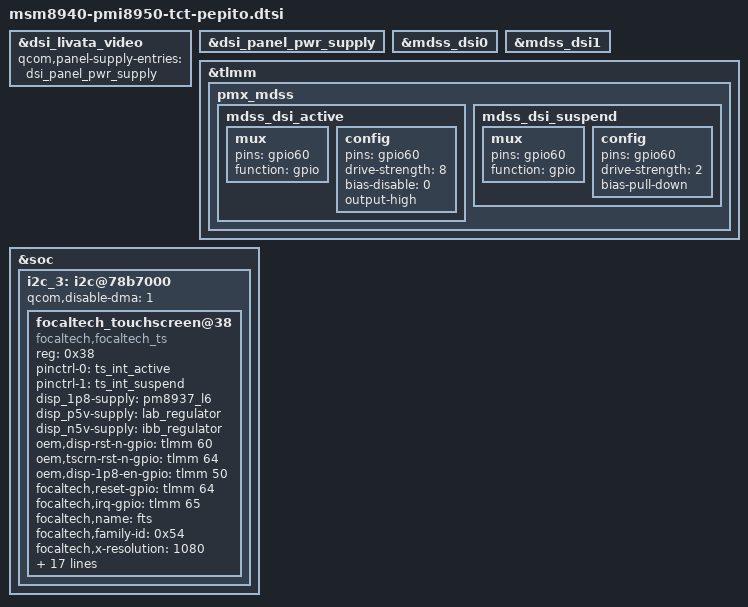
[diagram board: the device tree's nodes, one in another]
#include "dsi-panel-livata-juno-video.dtsi"
&dsi_livata_video {
	qcom,panel-supply-entries = <&dsi_panel_pwr_supply>;
};

&dsi_panel_pwr_supply {
	/* On Mercury, The touch driver controls vregs and gpios */
	/delete-node/ qcom,panel-supply-entry@1;
	/delete-node/ qcom,panel-supply-entry@2;
	/delete-node/ qcom,panel-supply-entry@3;
};

&mdss_dsi0 {
	/* On Mercury, The touch driver controls vregs and gpios */
	/delete-property/ vddio-supply;
	/delete-property/ lab-supply;
	/delete-property/ ibb-supply;

	/delete-property/ qcom,platform-enable-gpio;
	/delete-property/ qcom,5v-boost-gpio;
	/delete-property/ qcom,platform-bklight-en-gpio;
	/delete-property/ qcom,platform-reset-gpio;
};

&mdss_dsi1 {
	/* On Mercury, The touch driver controls vregs and gpios */
	/delete-property/ vddio-supply;
	/delete-property/ lab-supply;
	/delete-property/ ibb-supply;

	/delete-property/ qcom,platform-enable-gpio;
	/delete-property/ qcom,5v-boost-gpio;
	/delete-property/ qcom,platform-bklight-en-gpio;
	/delete-property/ qcom,platform-reset-gpio;
};

&tlmm {
	/delete-node/pmx_mdss;
	pmx_mdss: pmx_mdss {
		mdss_dsi_active: mdss_dsi_active {
			mux {
				pins = "gpio60";
				function = "gpio";
			};

			config {
				pins = "gpio60";
				drive-strength = <8>; /* 8 mA */
				bias-disable = <0>; /* no pull */
				output-high;
			};
		};

		mdss_dsi_suspend: mdss_dsi_suspend {
			mux {
				pins = "gpio60";
				function = "gpio";
			};

			config {
				pins = "gpio60";
				drive-strength = <2>; /* 2 mA */
				bias-pull-down; /* pull down */
			};
		};
	};
};
&soc {
	i2c_3: i2c@78b7000 { /* BLSP1 QUP3 */
		qcom,disable-dma = <1>;
		status = "okay";

		focaltech_touchscreen@38 {
			compatible = "focaltech,focaltech_ts";
			reg = <0x38>;
			/*interrupt-parent = <&msm_gpio>;*/
			/*interrupts = <13 0x8>;*/
			pinctrl-names = "on_state", "off_state";
			pinctrl-0 = <&ts_int_active>;
			pinctrl-1 = <&ts_int_suspend>;

			disp_1p8-supply     	= <&pm8937_l6>;
			disp_p5v-supply 	= <&lab_regulator>;
			disp_n5v-supply 	= <&ibb_regulator>;
			oem,disp-rst-n-gpio = <&tlmm 60 0x00>;
			oem,tscrn-rst-n-gpio = <&tlmm 64 0x00>;
			oem,disp-1p8-en-gpio = <&tlmm 50 0x00>;
			focaltech,reset-gpio = <&tlmm 64 0x00>;
			focaltech,irq-gpio = <&tlmm 65 0x00>;

			focaltech,name = "fts";
			focaltech,family-id = <0x54>;

			focaltech,x-resolution = <1080>;
			focaltech,y-resolution = <1620>;
			focaltech,display-coords = <0 0 1080 1640>;
			focaltech,panel-coords = <0 0 1080 1640>;
			focaltech,button-map= <180 360 540>;
			focaltech,no-force-update;
			focaltech,i2c-pull-up;
			focaltech,group-id = <1>;
			focaltech,hard-reset-delay-ms = <20>;
			focaltech,soft-reset-delay-ms = <150>;
			focaltech,num-max-touches = <10>;
			focaltech,fw-name = "FT_Upgrade_App.i";
			focaltech,fw-delay-aa-ms = <50>;
			focaltech,fw-delay-55-ms = <30>;
			focaltech,fw-upgrade-id1 = <0x79>;
			focaltech,fw-upgrade-id2 = <0x03>;
			focaltech,fw-delay-readid-ms = <10>;
			focaltech,fw-delay-era-flsh-ms = <2000>;
			status = "okay";
		};
	};
};
